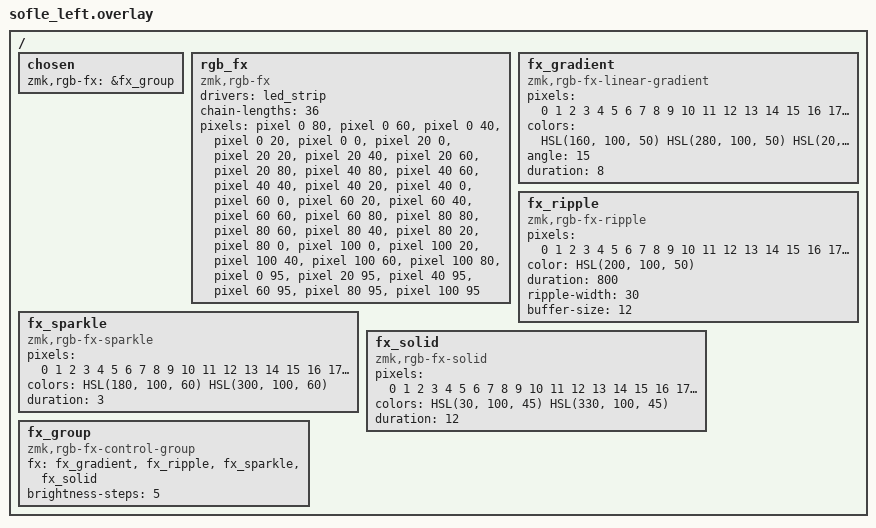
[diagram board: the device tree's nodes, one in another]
/*
 * RGB FX - left half (Sofle MX, 36 LEDs: per-key + underglow).
 *
 * PROVISIONAL LED MAP: chain order is a placeholder (standard Sofle RGB
 * serpentine + underglow). Update the (x,y) coordinates from the actual
 * PCB photo so ripple/gradients match the physical layout.
 */

#include <rgb_fx.dtsi>
#include <dt-bindings/zmk/rgb_fx.h>

/ {
    chosen {
        zmk,rgb-fx = &fx_group;
    };

    rgb_fx: rgb_fx {
        compatible = "zmk,rgb-fx";
        drivers = <&led_strip>;
        chain-lengths = <36>;
        pixels
            = <&pixel 0 80>, /*  0 perkey c0 r4 */
              <&pixel 0 60>, /*  1 perkey c0 r3 */
              <&pixel 0 40>, /*  2 perkey c0 r2 */
              <&pixel 0 20>, /*  3 perkey c0 r1 */
              <&pixel 0 0>, /*  4 perkey c0 r0 */
              <&pixel 20 0>, /*  5 perkey c1 r0 */
              <&pixel 20 20>, /*  6 perkey c1 r1 */
              <&pixel 20 40>, /*  7 perkey c1 r2 */
              <&pixel 20 60>, /*  8 perkey c1 r3 */
              <&pixel 20 80>, /*  9 perkey c1 r4 */
              <&pixel 40 80>, /* 10 perkey c2 r4 */
              <&pixel 40 60>, /* 11 perkey c2 r3 */
              <&pixel 40 40>, /* 12 perkey c2 r2 */
              <&pixel 40 20>, /* 13 perkey c2 r1 */
              <&pixel 40 0>, /* 14 perkey c2 r0 */
              <&pixel 60 0>, /* 15 perkey c3 r0 */
              <&pixel 60 20>, /* 16 perkey c3 r1 */
              <&pixel 60 40>, /* 17 perkey c3 r2 */
              <&pixel 60 60>, /* 18 perkey c3 r3 */
              <&pixel 60 80>, /* 19 perkey c3 r4 */
              <&pixel 80 80>, /* 20 perkey c4 r4 */
              <&pixel 80 60>, /* 21 perkey c4 r3 */
              <&pixel 80 40>, /* 22 perkey c4 r2 */
              <&pixel 80 20>, /* 23 perkey c4 r1 */
              <&pixel 80 0>, /* 24 perkey c4 r0 */
              <&pixel 100 0>, /* 25 perkey c5 r0 */
              <&pixel 100 20>, /* 26 perkey c5 r1 */
              <&pixel 100 40>, /* 27 perkey c5 r2 */
              <&pixel 100 60>, /* 28 perkey c5 r3 */
              <&pixel 100 80>, /* 29 perkey c5 r4 */
              <&pixel 0 95>, /* 30 underglow 0 */
              <&pixel 20 95>, /* 31 underglow 1 */
              <&pixel 40 95>, /* 32 underglow 2 */
              <&pixel 60 95>, /* 33 underglow 3 */
              <&pixel 80 95>, /* 34 underglow 4 */
              <&pixel 100 95>; /* 35 underglow 5 */
        /* key-pixels omitted (default 1:1) until the real map is known;
         * ripple uses key position -> pixel identity for now. */
    };

    fx_gradient: fx_gradient {
        compatible = "zmk,rgb-fx-linear-gradient";
        pixels = <0 1 2 3 4 5 6 7 8 9 10 11 12 13 14 15 16 17 18 19 20 21 22 23 24 25 26 27 28 29 30 31 32 33 34 35>;
        colors = <HSL(160, 100, 50) HSL(280, 100, 50) HSL(20, 100, 50)>;
        angle = <15>;
        duration = <8>;
    };

    fx_ripple: fx_ripple {
        compatible = "zmk,rgb-fx-ripple";
        pixels = <0 1 2 3 4 5 6 7 8 9 10 11 12 13 14 15 16 17 18 19 20 21 22 23 24 25 26 27 28 29 30 31 32 33 34 35>;
        color = <HSL(200, 100, 50)>;
        duration = <800>;
        ripple-width = <30>;
        buffer-size = <12>;
    };

    fx_sparkle: fx_sparkle {
        compatible = "zmk,rgb-fx-sparkle";
        pixels = <0 1 2 3 4 5 6 7 8 9 10 11 12 13 14 15 16 17 18 19 20 21 22 23 24 25 26 27 28 29 30 31 32 33 34 35>;
        colors = <HSL(180, 100, 60) HSL(300, 100, 60)>;
        duration = <3>;
    };

    fx_solid: fx_solid {
        compatible = "zmk,rgb-fx-solid";
        pixels = <0 1 2 3 4 5 6 7 8 9 10 11 12 13 14 15 16 17 18 19 20 21 22 23 24 25 26 27 28 29 30 31 32 33 34 35>;
        colors = <HSL(30, 100, 45) HSL(330, 100, 45)>;
        duration = <12>;
    };

    fx_group: fx_group {
        compatible = "zmk,rgb-fx-control-group";
        fx = <&fx_gradient &fx_ripple &fx_sparkle &fx_solid>;
        brightness-steps = <5>;
    };
};
